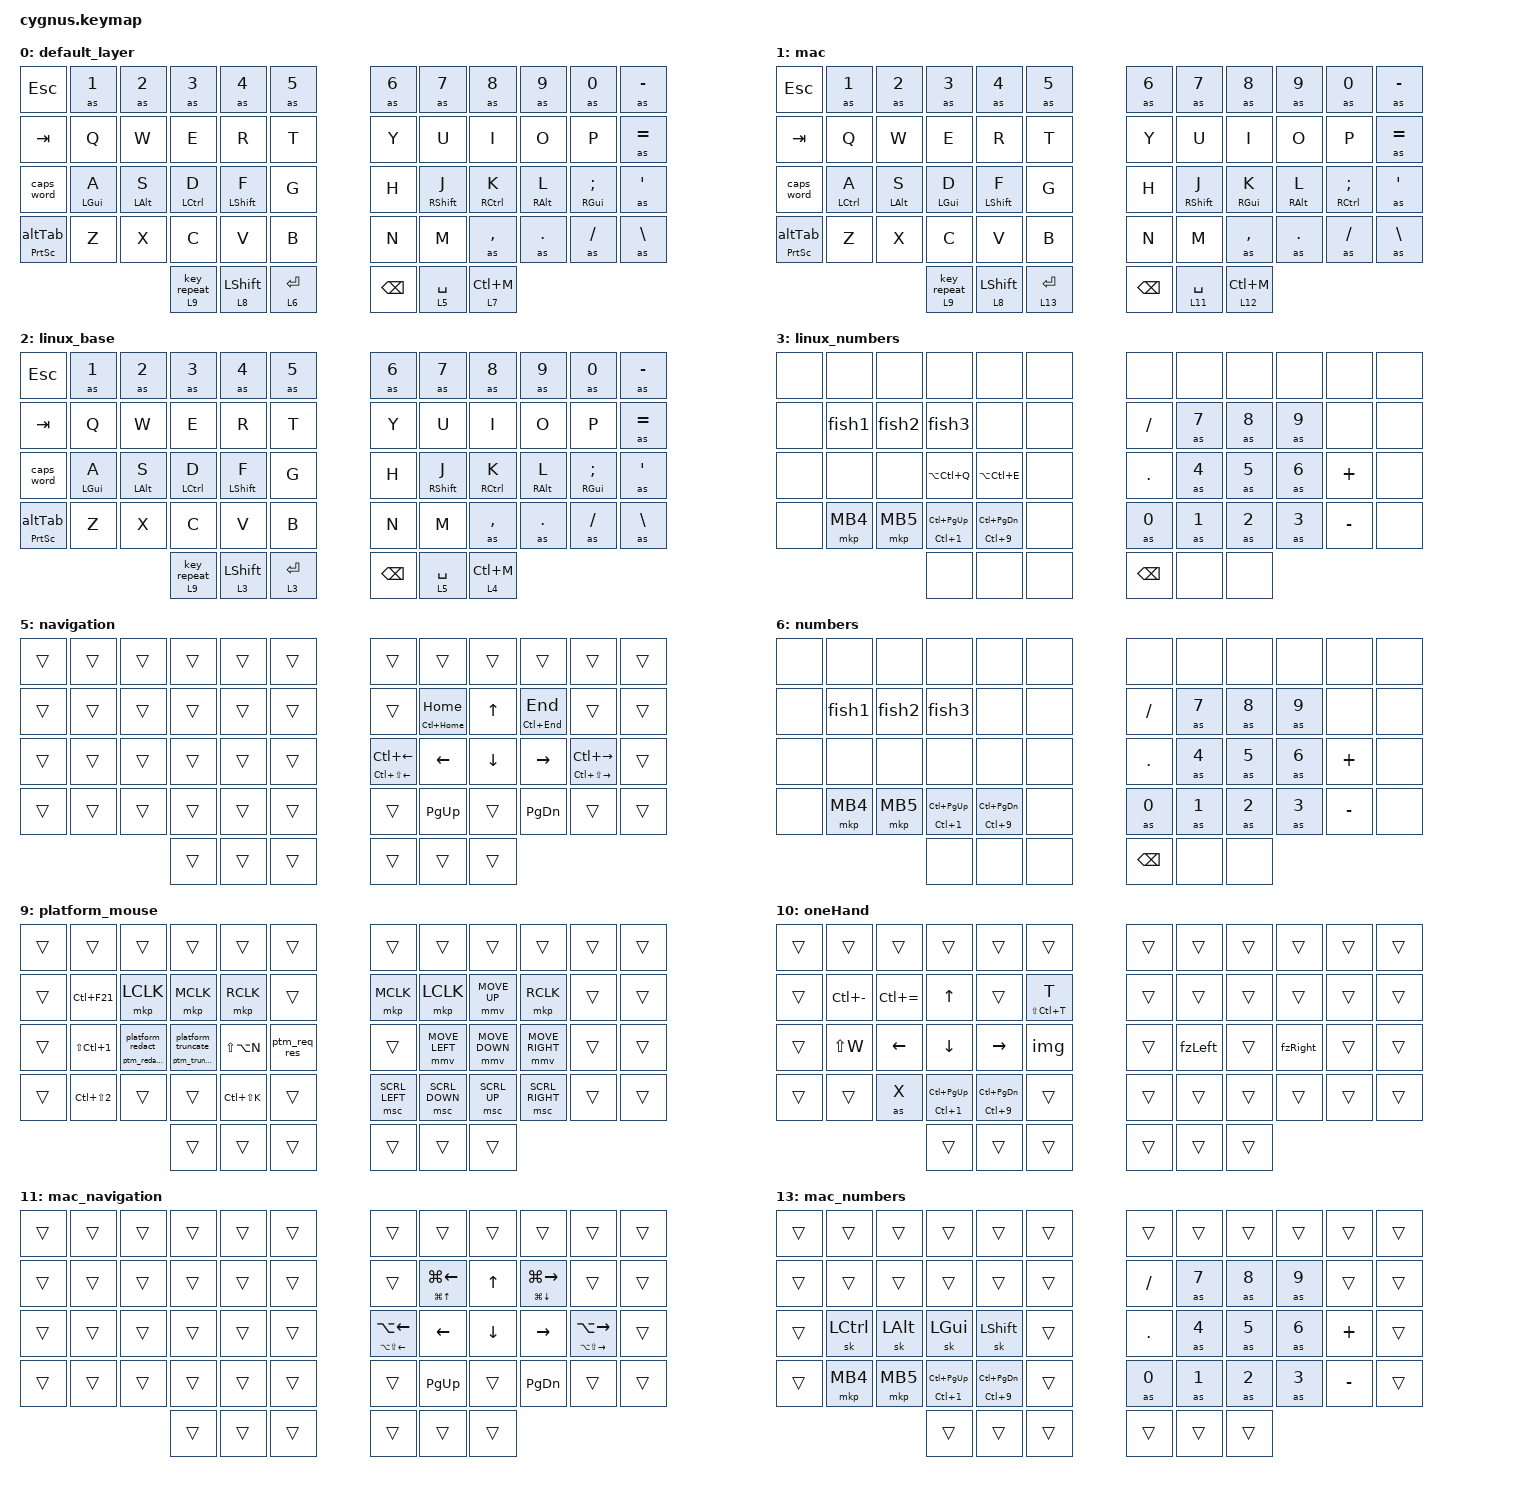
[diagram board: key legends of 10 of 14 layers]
#include <behaviors.dtsi>
#include <dt-bindings/zmk/keys.h>
#include <dt-bindings/zmk/pointing.h>

&sk { quick-release; };

/ {
    combos {
        compatible = "zmk,combos";

        copy {
            bindings = <&kp LC(C)>;
            key-positions = <38 39>;
            layers = <0 2>;
            require-prior-idle-ms = <150>;
        };

        paste {
            bindings = <&kp LC(V)>;
            key-positions = <39 40>;
            layers = <0 2>;
            require-prior-idle-ms = <150>;
        };

        del {
            bindings = <&holdTap LC(DELETE) DEL>;
            key-positions = <40 41>;
        };

        backtickTilde {
            bindings = <&as GRAVE>;
            key-positions = <13 14 15>;
        };

        oneHand {
            bindings = <&tog 10>;
            key-positions = <0 1 11 10>;
            layers = <0 10 2>;
        };

        esc {
            bindings = <&kp ESCAPE>;
            key-positions = <13 14>;
        };

        caps_word {
            bindings = <&caps_word>;
            key-positions = <31 28>;
        };

        ps_at {
            bindings = <&print_alt_tab PRINTSCREEN 0>;
            key-positions = <37 38>;
            layers = <0 2>;
            require-prior-idle-ms = <150>;
        };

        v_desktop_left {
            bindings = <&kp LG(LC(LEFT))>;
            key-positions = <42 43 44>;
            layers = <0 10>;
            require-prior-idle-ms = <150>;
        };

        v_desktop_right {
            bindings = <&kp LG(LC(RIGHT))>;
            key-positions = <43 44 45>;
            layers = <0 10>;
            require-prior-idle-ms = <150>;
        };

        tasks {
            bindings = <&holdTap LG(TAB) LC(LA(TAB))>;
            key-positions = <37 39>;
            require-prior-idle-ms = <200>;
            layers = <0>;
        };

        lbracket {
            bindings = <&as LEFT_BRACKET>;
            key-positions = <17 16>;
            require-prior-idle-ms = <200>;
        };

        rbracket {
            bindings = <&as RIGHT_BRACKET>;
            key-positions = <18 19>;
            require-prior-idle-ms = <200>;
        };

        altf4 {
            bindings = <&kp LA(F4)>;
            key-positions = <14 15 16 19 20 21>;
            require-prior-idle-ms = <200>;
            layers = <0 2>;
        };

        select_line {
            bindings = <&select_line>;
            key-positions = <21 20 19>;
            require-prior-idle-ms = <250>;
            layers = <0 2>;
        };

        mac_cp {
            bindings = <&kp LG(C)>;
            key-positions = <38 39>;
            require-prior-idle-ms = <200>;
            layers = <1>;
        };

        mac_pst {
            bindings = <&kp LG(V)>;
            key-positions = <40 39>;
            require-prior-idle-ms = <200>;
            layers = <1>;
        };

        mission_ctrl {
            bindings = <&hold_tap LC(DOWN) LC(UP_ARROW)>;
            key-positions = <39 37>;
            layers = <1>;
            require-prior-idle-ms = <200>;
        };

        ps_cmd_tab {
            bindings = <&hold_tap LS(LG(LC(NUMBER_4))) LG(TAB)>;
            key-positions = <37 38>;
            layers = <1>;
            require-prior-idle-ms = <200>;
        };

        mac_desktop_left {
            bindings = <&kp LC(LEFT)>;
            key-positions = <42 43 44>;
            layers = <1>;
            require-prior-idle-ms = <200>;
        };

        mac_desktop_right {
            bindings = <&kp LC(RIGHT)>;
            key-positions = <45 44 43>;
            layers = <1>;
            require-prior-idle-ms = <200>;
        };

        mac_sel_line {
            bindings = <&mac_select_line>;
            key-positions = <21 20 19>;
            layers = <1>;
            require-prior-idle-ms = <250>;
        };

        mac_delete_word {
            bindings = <&kp LA(BACKSPACE)>;
            key-positions = <51 32>;
            layers = <1>;
            require-prior-idle-ms = <150>;
        };

        mac_quit {
            bindings = <&hold_tap LG(Q) LG(W)>;
            key-positions = <20 21 19 15 14 16>;
            require-prior-idle-ms = <200>;
            layers = <1>;
        };

        mac_cycle {
            bindings = <&kp LG(GRAVE)>;
            key-positions = <37 38 39>;
            layers = <1>;
            require-prior-idle-ms = <200>;
        };

        mac_show_dock {
            bindings = <&kp LA(LG(D))>;
            key-positions = <39 40 41>;
            layers = <0>;
            require-prior-idle-ms = <150>;
        };

        dash {
            bindings = <&as MINUS>;
            key-positions = <21 20>;
            timeout-ms = <30>;
        };

        as_apos {
            bindings = <&as APOS>;
            key-positions = <32 33>;
        };

        ldr {
            bindings = <&leader1>;
            key-positions = <16 15>;
            layers = <0 1 2>;
            timeout-ms = <30>;
            require-prior-idle-ms = <250>;
        };

        tab {
            bindings = <&kp TAB>;
            key-positions = <26 27>;
            require-prior-idle-ms = <150>;
            timeout-ms = <30>;
        };

        linux_desktop_left {
            bindings = <&kp LC(LA(LEFT))>;
            key-positions = <42 43 44>;
            layers = <2>;
            require-prior-idle-ms = <150>;
        };

        linux_desktop_right {
            bindings = <&kp LC(LA(RIGHT))>;
            key-positions = <43 44 45>;
            layers = <2>;
            require-prior-idle-ms = <150>;
        };

        linux_gui {
            bindings = <&kp LC(LA(DOWN))>;
            key-positions = <37 39>;
            require-prior-idle-ms = <150>;
            layers = <2>;
        };
    };

    behaviors {
        hml: hml {
            compatible = "zmk,behavior-hold-tap";
            label = "HOME_ROW_LEFT";
            bindings = <&kp>, <&kp>;

            #binding-cells = <2>;
            hold-trigger-key-positions = <6 7 8 9 10 11 18 19 20 21 22 23 30 31 32 33 34 35 42 43 44 45 46 47>;
            tapping-term-ms = <180>;
            quick-tap-ms = <175>;
            require-prior-idle-ms = <150>;
            flavor = "balanced";
            hold-trigger-on-release;
        };

        hmr: hmr {
            compatible = "zmk,behavior-hold-tap";
            label = "HOME_ROW_RIGHT";
            bindings = <&kp>, <&kp>;

            #binding-cells = <2>;
            tapping-term-ms = <180>;
            quick-tap-ms = <175>;
            require-prior-idle-ms = <150>;
            flavor = "balanced";
            hold-trigger-key-positions = <0 1 2 3 4 5 12 13 14 15 16 17 24 25 26 27 28 29 36 37 38 39 40 41>;
            hold-trigger-on-release;
        };

        layer_sticky: layer_sticky {
            compatible = "zmk,behavior-hold-tap";
            label = "LAYER_STICKY";
            bindings = <&mo>, <&sk>;

            #binding-cells = <2>;
            tapping-term-ms = <150>;
            flavor = "balanced";
        };

        holdTap: holdTap {
            compatible = "zmk,behavior-hold-tap";
            label = "HOLDTAP";
            bindings = <&kp>, <&kp>;

            #binding-cells = <2>;
            tapping-term-ms = <200>;
        };

        hold_AT: hold_AT {
            compatible = "zmk,behavior-hold-tap";
            label = "HOLD_AT";
            bindings = <&kp>, <&altTab>;

            #binding-cells = <2>;
            tapping-term-ms = <200>;
        };

        as_ht: auto_shift_hold_tap {
            compatible = "zmk,behavior-hold-tap";
            label = "AUTO_SHIFT_HOLD_TAP";
            bindings = <&shift>, <&kp>;

            #binding-cells = <2>;
            tapping-term-ms = <200>;
            flavor = "balanced";
        };

        fz_left: fz_left {
            compatible = "zmk,behavior-hold-tap";
            label = "FZ_LEFT";
            bindings = <&kp>, <&fzLeft>;

            #binding-cells = <2>;
            tapping-term-ms = <200>;
        };

        fz_right: fz_right {
            compatible = "zmk,behavior-hold-tap";
            label = "FZ_RIGHT";
            bindings = <&kp>, <&fzRight>;

            #binding-cells = <2>;
            tapping-term-ms = <200>;
        };

        ac_browser: ac_browser {
            compatible = "zmk,behavior-tap-dance";
            label = "AC_BROWSER";
            #binding-cells = <0>;
            bindings =
                <&holdTap LA(LS(LC(V))) LS(LA(LC(Q)))>,
                <&kp LS(LA(LC(X)))>;
        };

        ac_VMs: ac_VMs {
            compatible = "zmk,behavior-tap-dance";
            label = "AC_VMS";
            #binding-cells = <0>;
            bindings = <&kp LS(LA(LC(W)))>, <&kp LS(LA(LC(I)))>;
        };

        burp_rep: burp_rep {
            compatible = "zmk,behavior-tap-dance";
            label = "BURP_REP";
            #binding-cells = <0>;
            bindings = <&kp LS(LC(R))>, <&kp LC(R)>;
        };

        burp_proxy: burp_proxy {
            compatible = "zmk,behavior-tap-dance";
            label = "BURP_PROXY";
            #binding-cells = <0>;
            bindings = <&kp LS(LC(P))>, <&kp LC(T)>;
        };

        burp_intruder: burp_intruder {
            compatible = "zmk,behavior-tap-dance";
            label = "BURP_INTRUDER";
            #binding-cells = <0>;
            bindings = <&holdTap LC(P) LS(LC(I))>, <&kp LC(I)>;
        };

        burp_org: burp_org {
            compatible = "zmk,behavior-tap-dance";
            label = "BURP_ORG";
            #binding-cells = <0>;
            bindings = <&kp LS(LC(O))>, <&kp LC(O)>;
        };

        burp_send: burp_send {
            compatible = "zmk,behavior-tap-dance";
            label = "BURP_SEND";
            #binding-cells = <0>;
            bindings = <&kp LC(SPACE)>, <&kp LS(LC(SPACE))>;
        };

        burp_dash: burp_dash {
            compatible = "zmk,behavior-tap-dance";
            label = "BURP_DASH";
            #binding-cells = <0>;
            bindings = <&holdTap LS(LC(NUMBER_9)) LC(LS(D))>, <&kp LS(LC(T))>;
        };

        burp_fwd: burp_fwd {
            compatible = "zmk,behavior-tap-dance";
            label = "BURP_FWD";
            #binding-cells = <0>;
            bindings = <&kp LC(F)>, <&kp LS(LC(F))>;
        };

        burp_notes_htmlE: burp_notes_htmlE {
            compatible = "zmk,behavior-tap-dance";
            label = "BURP_NOTES_HTMLE";
            #binding-cells = <0>;
            bindings = <&kp LC(LA(N))>, <&kp LC(LA(H))>;
        };

        mouse_layer_toggle: mouse_layer_toggle {
            compatible = "zmk,behavior-tap-dance";
            label = "MOUSE_LAYER_TOGGLE";
            #binding-cells = <0>;
            bindings = <&lt 9 LG(LS(D))>, <&tog 9>;
        };

        ptm_req_res: ptm_req_res {
            compatible = "zmk,behavior-tap-dance";
            label = "PTM_REQ_RES";
            #binding-cells = <0>;
            bindings = <&ptm_req>, <&ptm_res>;
        };

        truncate: truncate {
            compatible = "zmk,behavior-hold-tap";
            label = "TRUNCATE";
            bindings = <&ptm_truncated>, <&platform_truncate>;

            #binding-cells = <2>;
            tapping-term-ms = <200>;
            flavor = "balanced";
        };

        redact: redact {
            compatible = "zmk,behavior-hold-tap";
            label = "REDACT";
            bindings = <&ptm_redacted>, <&platform_redact>;

            #binding-cells = <2>;
            flavor = "balanced";
            tapping-term-ms = <200>;
        };

        print_alt_tab: print_alt_tab {
            compatible = "zmk,behavior-hold-tap";
            label = "PRINT_ALT_TAB";
            bindings = <&kp>, <&altTab>;

            #binding-cells = <2>;
            flavor = "balanced";
            tapping-term-ms = <150>;
        };

        hrm: hrm {
            compatible = "zmk,behavior-hold-tap";
            label = "HRM";
            bindings = <&kp>, <&kp>;

            #binding-cells = <2>;
            tapping-term-ms = <280>;
            quick-tap-ms = <175>;
            require-prior-idle-ms = <150>;
            flavor = "balanced";
            hold-trigger-on-release;
        };

        ht_layer: ht_layer {
            compatible = "zmk,behavior-hold-tap";
            label = "HT_LAYER";
            bindings = <&mo>, <&kp>;

            #binding-cells = <2>;
            tapping-term-ms = <200>;
            quick-tap-ms = <175>;
            flavor = "tap-preferred";
        };

        hold_tap: hold_tap {
            compatible = "zmk,behavior-hold-tap";
            label = "HOLD_TAP";
            bindings = <&kp>, <&kp>;

            #binding-cells = <2>;
            tapping-term-ms = <180>;
            flavor = "balanced";
        };

        burp_int: burp_int {
            compatible = "zmk,behavior-tap-dance";
            label = "BURP_INT";
            #binding-cells = <0>;
            bindings = <&hold_tap LC(P) LC(LS(I))>, <&kp LC(I)>;

            tapping-term-ms = <300>;
        };

        burp_notes_highlight: burp_notes_highlight {
            compatible = "zmk,behavior-tap-dance";
            label = "BURP_NOTES_HIGHLIGHT";
            #binding-cells = <0>;
            bindings = <&kp LC(LA(N))>, <&kp LC(LA(H))>;

            tapping-term-ms = <300>;
        };

        ac_vm: ac_vm {
            compatible = "zmk,behavior-tap-dance";
            label = "AC_VM";
            #binding-cells = <0>;
            bindings = <&kp LA(LS(LC(W)))>, <&kp LS(LC(LA(I)))>;
        };

        ptm_code_block: ptm_code_block {
            compatible = "zmk,behavior-tap-dance";
            label = "PTM_CODE_BLOCK";
            #binding-cells = <0>;
            bindings = <&ptm_request>, <&ptm_response>;
        };

        caps: caps {
            compatible = "zmk,behavior-hold-tap";
            label = "CAPS";
            bindings = <&caps_word>, <&sk>;

            #binding-cells = <2>;
            tapping-term-ms = <200>;
            flavor = "balanced";
        };

        ps_at: ps_at {
            compatible = "zmk,behavior-hold-tap";
            label = "PS_AT";
            bindings = <&kp>, <&alt_tab>;

            #binding-cells = <2>;
            tapping-term-ms = <200>;
        };

        burp_rep_with_shift: burp_rep_with_shift {
            compatible = "zmk,behavior-hold-tap";
            label = "BURP_REP_WITH_SHIFT";
            bindings = <&kp>, <&burp_rep>;

            #binding-cells = <2>;
            tapping-term-ms = <200>;
            flavor = "balanced";
        };

        fz_left_both: fz_left_both {
            compatible = "zmk,behavior-hold-tap";
            label = "FZ_LEFT_BOTH";
            bindings = <&kp>, <&fz_left>;

            #binding-cells = <2>;
            tapping-term-ms = <200>;
            flavor = "balanced";
        };

        os_shift_layer_change: os_shift_layer_change {
            compatible = "zmk,behavior-hold-tap";
            label = "OS_SHIFT_LAYER_CHANGE";
            bindings = <&mo>, <&sticky_shift>;

            #binding-cells = <2>;
            tapping-term-ms = <200>;
            flavor = "balanced";
        };

        fz_left_macro: fz_left_macro {
            compatible = "zmk,behavior-hold-tap";
            label = "FZ_LEFT_MACRO";
            bindings = <&fz_expand_left>, <&fz_left>;

            #binding-cells = <2>;
            tapping-term-ms = <200>;
            flavor = "balanced";
        };

        fz_right_macro: fz_right_macro {
            compatible = "zmk,behavior-hold-tap";
            label = "FZ_RIGHT_MACRO";
            bindings = <&fz_expand_right>, <&fz_right>;

            #binding-cells = <2>;
            tapping-term-ms = <200>;
            flavor = "balanced";
        };

        repeat_layer: repeat_layer {
            compatible = "zmk,behavior-hold-tap";
            label = "REPEAT_LAYER";
            bindings = <&mo>, <&key_repeat>;

            #binding-cells = <2>;
            tapping-term-ms = <200>;
        };

        leader1: leader1 {
            compatible = "zmk,behavior-leader-key";
            #binding-cells = <0>;

            os_mac {
                sequence = <O M>;
                bindings = <&to 1>;
            };

            os_win {
                sequence = <O W>;
                bindings = <&to 0>;
            };

            os_linux {
                sequence = <O L>;
                bindings = <&to 2>;
            };

            p_netspi {
                sequence = <P N>;
                bindings = <&fish1>;
            };

            p_aws {
                sequence = <P A>;
                bindings = <&fish2>;
            };

            p_mac {
                sequence = <P M>;
                bindings = <&fish3>;
            };

            w_netspi {
                sequence = <W N>;
                bindings = <&word_netspi>;
            };

            w_signoff {
                sequence = <W S>;
                bindings = <&word_signoff_cmd>;
            };

            w_code_block {
                sequence = <W C>;
                bindings = <&ptm_codeBlock>;
            };

            l_check_mem {
                sequence = <L M>;
                bindings = <&linux_check_mem>;
            };

            l_ssh {
                sequence = <L S>;
                bindings = <&linux_ssh>;
            };

            l_check_drives {
                sequence = <L D>;
                bindings = <&linux_check_mounted_drives>;
            };
        };
    };

    macros {
        altTab: altTab {
            compatible = "zmk,behavior-macro";
            #binding-cells = <0>;
            bindings = <&kt LEFT_ALT &kp TAB &kt LEFT_ALT>;
            label = "ALTTAB";
            wait-ms = <200>;
        };

        alt_tab: alt_tab {
            compatible = "zmk,behavior-macro";
            #binding-cells = <0>;
            bindings = <&kt LEFT_ALT &kp TAB &kt LEFT_ALT>;
            label = "ALT_TAB";
            tap-ms = <150>;
        };

        fish1: pw {
            compatible = "zmk,behavior-macro";
            #binding-cells = <0>;
            bindings = <&kp N0 &kp N0 &kp PERIOD &kp N0 &kp N0 &kp N3 &kp A &kp Q &kp H &kp Q &kp C &kp Y &kp B &kp N0 &kp N0 &kp DOT &kp N0 &kp N0>;
            label = "PW";
        };

        shift: new_macro {
            compatible = "zmk,behavior-macro-one-param";
            #binding-cells = <1>;
            bindings =
                <&macro_press>,
                <&kp LEFT_SHIFT>,
                <&macro_tap>,
                <&macro_param_1to1 &kp MACRO_PLACEHOLDER>,
                <&macro_release>,
                <&kp LEFT_SHIFT>;

            label = "NEW_MACRO";
        };

        as: as {
            compatible = "zmk,behavior-macro-one-param";
            #binding-cells = <1>;
            bindings =
                <&macro_press>,
                <&macro_param_1to1 &macro_param_1to2 &as_ht MACRO_PLACEHOLDER MACRO_PLACEHOLDER>,
                <&macro_pause_for_release>,
                <&macro_release>,
                <&macro_param_1to1 &macro_param_1to2 &as_ht MACRO_PLACEHOLDER MACRO_PLACEHOLDER>;

            label = "AS";
        };

        fzLeft: fzLeft {
            compatible = "zmk,behavior-macro";
            #binding-cells = <0>;
            bindings = <&kt LEFT_GUI &kp LEFT &kt LEFT_GUI>;
            label = "FZLEFT";
            tap-ms = <100>;
        };

        fzRight: fzRight {
            compatible = "zmk,behavior-macro";
            #binding-cells = <0>;
            bindings = <&kt LEFT_GUI &kp RIGHT &kt LEFT_GUI>;
            label = "FZRIGHT";
            tap-ms = <100>;
        };

        sticky_shift: sticky_shift {
            compatible = "zmk,behavior-macro";
            #binding-cells = <0>;
            bindings = <&sk LEFT_SHIFT>;
            label = "STICKY_SHIFT";
        };

        fzUp: fzUp {
            compatible = "zmk,behavior-macro";
            #binding-cells = <0>;
            bindings = <&kt LEFT_GUI &kp UP_ARROW &kt LEFT_GUI>;
            label = "FZUP";
            tap-ms = <100>;
        };

        fzDown: fzDown {
            compatible = "zmk,behavior-macro";
            #binding-cells = <0>;
            bindings = <&kt LEFT_GUI &kp DOWN &kt LEFT_GUI>;
            label = "FZDOWN";
            tap-ms = <100>;
        };

        fz_expand_left: fz_expand_left {
            compatible = "zmk,behavior-macro";
            #binding-cells = <0>;
            bindings = <&kt LEFT_GUI &kt LEFT_ALT &kt LCTRL &kt LEFT &kt LEFT_GUI &kt LALT &kt LCTRL>;
            label = "FZ_EXPAND_LEFT";
            tap-ms = <50>;
        };

        fz_expand_right: fz_expand_right {
            compatible = "zmk,behavior-macro";
            #binding-cells = <0>;
            bindings = <&kt LEFT_GUI &kt LEFT_ALT &kt LCTRL &kt RIGHT &kt LEFT_GUI &kt LALT &kt LCTRL>;
            label = "FZ_EXPAND_RIGHT";
            tap-ms = <50>;
        };

        img: img {
            compatible = "zmk,behavior-macro";
            #binding-cells = <0>;
            bindings = <&mkp RCLK &kp I>;
            label = "IMG";
            tap-ms = <300>;
        };

        close: close {
            compatible = "zmk,behavior-macro";
            #binding-cells = <0>;
            bindings = <&kt LEFT_ALT &kp F4 &kt LEFT_ALT>;
            label = "CLOSE";
            tap-ms = <200>;
        };

        select_line: select_line {
            compatible = "zmk,behavior-macro";
            #binding-cells = <0>;
            bindings = <&kp HOME &kp LS(END)>;
            label = "SELECT_LINE";
            tap-ms = <100>;
        };

        double_click: double_click {
            compatible = "zmk,behavior-macro";
            #binding-cells = <0>;
            bindings = <&mkp MB1 &mkp MB1>;
            label = "DOUBLE_CLICK";
            tap-ms = <50>;
        };

        shift_click: shift_click {
            compatible = "zmk,behavior-macro";
            #binding-cells = <0>;
            bindings = <&kt LC(LEFT_SHIFT) &mkp MB1 &kt LC(LEFT_SHIFT)>;
            label = "SHIFT_CLICK";
        };

        mac_select_line: mac_select_line {
            compatible = "zmk,behavior-macro";
            #binding-cells = <0>;
            bindings = <&kp LG(LEFT) &kp LS(LG(RIGHT))>;
            label = "MAC_SELECT_LINE";
        };

        ptm_codeBlock: ptm_codeBlock {
            compatible = "zmk,behavior-macro";
            #binding-cells = <0>;
            bindings = <&kp GRAVE &kp GRAVE &kp GRAVE &kp ENTER &kp ENTER &kp GRAVE &kp GRAVE &kp GRAVE &kp UP_ARROW>;
            label = "PTM_CODEBLOCK";
        };

        fish2: pw2 {
            compatible = "zmk,behavior-macro";
            #binding-cells = <0>;
            bindings = <&kp N3 &kp A &kp Q &kp H &kp Q &kp C &kp Y &kp B &kp N0 &kp DOT &kp N0>;
            label = "PW2";
        };

        ptm_req: ptm_req {
            compatible = "zmk,behavior-macro";
            #binding-cells = <0>;
            bindings = <&kp STAR &kp STAR &kp LS(R) &kp E &kp Q &kp U &kp E &kp S &kp T &kp COLON &kp STAR &kp STAR &kp RET &kp GRAVE &kp GRAVE &kp GRAVE &kp RET &kp RET &kp GRAVE &kp GRAVE &kp GRAVE &kp UP_ARROW>;
            label = "PTM_REQ";
        };

        ptm_request: ptm_request {
            compatible = "zmk,behavior-macro";
            #binding-cells = <0>;
            bindings = <&kp STAR &kp STAR &kp LS(R) &kp E &kp Q &kp U &kp E &kp S &kp T &kp COLON &kp STAR &kp STAR &kp RET &kp GRAVE &kp GRAVE &kp GRAVE &kp RET &kp RET &kp GRAVE &kp GRAVE &kp GRAVE &kp UP_ARROW>;
            label = "PTM_REQUEST";
        };

        ptm_res: ptm_res {
            compatible = "zmk,behavior-macro";
            #binding-cells = <0>;
            bindings = <&kp STAR &kp STAR &kp LS(R) &kp E &kp S &kp P &kp O &kp N &kp S &kp E &kp COLON &kp STAR &kp STAR &kp RET &kp GRAVE &kp GRAVE &kp GRAVE &kp RET &kp RET &kp GRAVE &kp GRAVE &kp GRAVE &kp UP_ARROW>;
            label = "PTM_RES";
        };

        ptm_response: ptm_response {
            compatible = "zmk,behavior-macro";
            #binding-cells = <0>;
            bindings = <&kp STAR &kp STAR &kp LS(R) &kp E &kp S &kp P &kp O &kp N &kp S &kp E &kp COLON &kp STAR &kp STAR &kp RET &kp GRAVE &kp GRAVE &kp GRAVE &kp RET &kp RET &kp GRAVE &kp GRAVE &kp GRAVE &kp UP_ARROW>;
            label = "PTM_RESPONSE";
        };

        ptm_redacted: ptm_redacted {
            compatible = "zmk,behavior-macro";
            #binding-cells = <0>;
            bindings = <&kp LBKT &kp LS(R) &kp LS(E) &kp LS(D) &kp LS(A) &kp LS(C) &kp LS(T) &kp LS(E) &kp LS(D) &kp RBKT>;
            label = "PTM_REDACTED";
        };

        ptm_truncated: ptm_truncated {
            compatible = "zmk,behavior-macro";
            #binding-cells = <0>;
            bindings = <&kp LBKT &kp LS(T) &kp LS(R) &kp LS(U) &kp LS(N) &kp LS(C) &kp LS(A) &kp LS(T) &kp LS(E) &kp LS(D) &kp RBKT>;
            label = "PTM_TRUNCATED";
        };

        platform_truncate: platform_truncate {
            compatible = "zmk,behavior-macro";
            #binding-cells = <0>;
            bindings = <&kp LS(LA(T))>;
            label = "PLATFORM_TRUNCATE";
        };

        platform_redact: platform_redact {
            compatible = "zmk,behavior-macro";
            #binding-cells = <0>;
            bindings = <&kp LS(LA(R))>;
            label = "PLATFORM_REDACT";
        };

        fish3: fish3 {
            compatible = "zmk,behavior-macro";
            #binding-cells = <0>;
            bindings = <&kp N0 &kp N0 &kp DOT &kp N0 &kp N0 &kp N3 &kp A &kp Q &kp H &kp Q &kp C &kp Y &kp LS(B) &kp N0 &kp N0 &kp DOT &kp N0 &kp N0>;
            label = "FISH3";
        };

        word_netspi: word_netspi {
            compatible = "zmk,behavior-macro";
            #binding-cells = <0>;
            bindings = <&kp LS(N) &kp E &kp T &kp LS(S) &kp LS(P) &kp LS(I)>;
            label = "WORD_NETSPI";
        };

        word_signoff_cmd: word_signoff_cmd {
            compatible = "zmk,behavior-macro";
            #binding-cells = <0>;
            bindings = <&kp GRAVE &kp FSLH &kp S &kp D &kp L &kp MINUS &kp M &kp E &kp D &kp I &kp U &kp M &kp MINUS &kp S &kp I &kp G &kp N &kp O &kp F &kp F &kp GRAVE>;
            label = "WORD_SIGNOFF_CMD";
        };

        linux_check_mem: linux_check_mem {
            compatible = "zmk,behavior-macro";
            #binding-cells = <0>;
            bindings = <&kp F &kp R &kp E &kp E &kp SPACE &kp MINUS &kp H>;
            label = "LINUX_CHECK_MEM";
        };

        linux_ssh: linux_ssh {
            compatible = "zmk,behavior-macro";
            #binding-cells = <0>;
            bindings = <&kp S &kp S &kp H &kp SPACE &kp S &kp U &kp N &kp G &kp AT &kp S &kp U &kp N &kp G &kp MINUS &kp S &kp E &kp R &kp V &kp E &kp R>;
            label = "LINUX_SSH";
        };

        linux_check_mounted_drives: linux_check_mounted_drives {
            compatible = "zmk,behavior-macro";
            #binding-cells = <0>;
            bindings = <&kp L &kp S &kp B &kp L &kp K &kp SPACE &kp MINUS &kp F>;
            label = "LINUX_CHECK_MOUNTED_DRIVES";
        };
    };

    keymap {
        compatible = "zmk,keymap";

        default_layer {
            // -----------------------------------------------------------------------------------------
            // |  ESC |  1  |  2  |  3  |  4  |  5  |   |  6  |  7   |  8  |  9  |  0  |  ?   |
            // |  TAB |  Q  |  W  |  E  |  R  |  T  |   |  Y  |  U   |  I  |  O  |  P  | BKSP |
            // | CTRL |  A  |  S  |  D  |  F  |  G  |   |  H  |  J   |  K  |  L  |  ;  |  '   |
            // | SHFT |  Z  |  X  |  C  |  V  |  B  |   |  N  |  M   |  ,  |  .  |  /  | ESC  |
            //                    | GUI | LWR | SPC |   | ENT | RSE  | ALT |

            bindings = <
&kp ESCAPE              &as N1           &as N2           &as N3               &as N4                      &as N5         &as N6         &as N7              &as N8        &as N9            &as N0               &as MINUS
&kp TAB                 &kp Q            &kp W            &kp E                &kp R                       &kp T          &kp Y          &kp U               &kp I         &kp O             &kp P                &as EQUAL
&caps_word              &hml LEFT_GUI A  &hml LEFT_ALT S  &hml LEFT_CONTROL D  &hml LEFT_SHIFT F           &kp G          &kp H          &hmr RIGHT_SHIFT J  &hmr RCTRL K  &hmr RIGHT_ALT L  &hmr RIGHT_GUI SEMI  &as SQT
&hold_AT PRINTSCREEN 0  &kp Z            &kp X            &kp C                &kp V                       &kp B          &kp N          &kp M               &as COMMA     &as DOT           &as SLASH            &as BSLH
                                                          &repeat_layer 9 0    &layer_sticky 8 LEFT_SHIFT  &lt 6 ENTER    &kp BACKSPACE  &lt 5 SPACE         &lt 7 LC(M)
            >;
        };

        mac {
            bindings = <
&kp ESCAPE              &as N1        &as N2           &as N3             &as N4                      &as N5          &as N6         &as N7              &as N8            &as N9            &as N0           &as MINUS
&kp TAB                 &kp Q         &kp W            &kp E              &kp R                       &kp T           &kp Y          &kp U               &kp I             &kp O             &kp P            &as EQUAL
&caps_word              &hml LCTRL A  &hml LEFT_ALT S  &hml LEFT_GUI D    &hml LEFT_SHIFT F           &kp G           &kp H          &hmr RIGHT_SHIFT J  &hmr RIGHT_GUI K  &hmr RIGHT_ALT L  &hmr RCTRL SEMI  &as SQT
&hold_AT PRINTSCREEN 0  &kp Z         &kp X            &kp C              &kp V                       &kp B           &kp N          &kp M               &as COMMA         &as DOT           &as SLASH        &as BSLH
                                                       &repeat_layer 9 0  &layer_sticky 8 LEFT_SHIFT  &lt 13 ENTER    &kp BACKSPACE  &lt 11 SPACE        &lt 12 LC(M)
            >;
        };

        linux_base {
            bindings = <
&kp ESCAPE              &as N1           &as N2           &as N3               &as N4                      &as N5         &as N6         &as N7              &as N8        &as N9            &as N0               &as MINUS
&kp TAB                 &kp Q            &kp W            &kp E                &kp R                       &kp T          &kp Y          &kp U               &kp I         &kp O             &kp P                &as EQUAL
&caps_word              &hml LEFT_GUI A  &hml LEFT_ALT S  &hml LEFT_CONTROL D  &hml LEFT_SHIFT F           &kp G          &kp H          &hmr RIGHT_SHIFT J  &hmr RCTRL K  &hmr RIGHT_ALT L  &hmr RIGHT_GUI SEMI  &as SQT
&hold_AT PRINTSCREEN 0  &kp Z            &kp X            &kp C                &kp V                       &kp B          &kp N          &kp M               &as COMMA     &as DOT           &as SLASH            &as BSLH
                                                          &repeat_layer 9 0    &layer_sticky 3 LEFT_SHIFT  &lt 3 ENTER    &kp BACKSPACE  &lt 5 SPACE         &lt 4 LC(M)
            >;
        };

        linux_numbers {
            bindings = <
&none  &none     &none     &none                            &none                          &none    &none          &none         &none         &none         &none      &none
&none  &fish1    &fish2    &fish3                           &none                          &none    &kp SLASH      &as N7        &as N8        &as N9        &none      &none
&none  &none     &none     &kp LA(LC(Q))                    &kp LA(LC(E))                  &none    &kp PERIOD     &as NUMBER_4  &as N5        &as NUMBER_6  &kp PLUS   &none
&none  &mkp MB4  &mkp MB5  &holdTap LC(NUMBER_1) LC(PG_UP)  &holdTap LC(N9) LC(PAGE_DOWN)  &none    &as N0         &as NUMBER_1  &as NUMBER_2  &as NUMBER_3  &kp MINUS  &none
                           &none                            &none                          &none    &kp BACKSPACE  &none         &none
            >;
        };

        linux_media {
            bindings = <
&trans  &trans                    &trans                       &trans                    &trans                         &trans    &trans  &trans             &trans            &trans           &trans  &trans
&trans  &kp LC(LG(LA(NUMBER_1)))  &kp LC(LG(LA(NUMBER_2)))     &kp LC(LG(LA(NUMBER_3)))  &kp LC(LA(LG(NUMBER_4)))       &trans    &trans  &kp C_VOLUME_DOWN  &kp C_MUTE        &kp C_VOLUME_UP  &trans  &trans
&trans  &trans                    &fz_left LA(LC(LG(LEFT))) 0  &trans                    &fz_right LA(LC(LG(RIGHT))) 0  &trans    &trans  &kp C_PREV         &kp C_PLAY_PAUSE  &kp C_NEXT       &trans  &trans
&trans  &trans                    &trans                       &trans                    &trans                         &trans    &trans  &trans             &trans            &trans           &trans  &trans
                                                               &trans                    &trans                         &trans    &trans  &trans             &trans
            >;
        };

        navigation {
            // -----------------------------------------------------------------------------------------
            // |  TAB |  F1 |  F2 |  F3 |  F4 |  F5 |   |  F6 |  F7 |  F8 |  F9 | F10 | BKSP |
            // |  TAB |  1  |  2  |  3  |  4  |  5  |   |  6  |  7  |  8  |  9  |  0  | BKSP |
            // | BTCLR| BT1 | BT2 | BT3 | BT4 | BT5 |   | LFT | DWN |  UP | RGT |     |      |
            // | SHFT |     |     |     |     |     |   |     |     |     |     |     |      |
            //                    | GUI |     | SPC |   | ENT |     | ALT |

            bindings = <
&trans  &trans  &trans  &trans  &trans  &trans    &trans                          &trans                  &trans        &trans                &trans                            &trans
&trans  &trans  &trans  &trans  &trans  &trans    &trans                          &holdTap LC(HOME) HOME  &kp UP_ARROW  &holdTap LC(END) END  &trans                            &trans
&trans  &trans  &trans  &trans  &trans  &trans    &holdTap LC(LS(LEFT)) LC(LEFT)  &kp LEFT                &kp DOWN      &kp RIGHT             &holdTap LC(LS(RIGHT)) LC(RIGHT)  &trans
&trans  &trans  &trans  &trans  &trans  &trans    &trans                          &kp PAGE_UP             &trans        &kp PAGE_DOWN         &trans                            &trans
                        &trans  &trans  &trans    &trans                          &trans                  &trans
            >;
        };

        numbers {
            bindings = <
&none  &none     &none     &none                            &none                          &none    &none          &none         &none         &none         &none      &none
&none  &fish1    &fish2    &fish3                           &none                          &none    &kp SLASH      &as N7        &as N8        &as N9        &none      &none
&none  &none     &none     &none                            &none                          &none    &kp PERIOD     &as NUMBER_4  &as N5        &as NUMBER_6  &kp PLUS   &none
&none  &mkp MB4  &mkp MB5  &holdTap LC(NUMBER_1) LC(PG_UP)  &holdTap LC(N9) LC(PAGE_DOWN)  &none    &as N0         &as NUMBER_1  &as NUMBER_2  &as NUMBER_3  &kp MINUS  &none
                           &none                            &none                          &none    &kp BACKSPACE  &none         &none
            >;
        };

        fz_media_browser {
            // -----------------------------------------------------------------------------------------
            // |  TAB |  !  |  @  |  #  |  $  |  %  |   |  ^  |  &  |  *  |  (  |  )  | BKSP |
            // | CTRL |     |     |     |     |     |   |  -  |  =  |  [  |  ]  |  \  |  `   |
            // | SHFT |     |     |     |     |     |   |  _  |  +  |  {  |  }  | "|" |  ~   |
            //                    | GUI |     | SPC |   | ENT |     | ALT |

            bindings = <
&trans  &trans  &trans                       &trans   &trans                         &trans    &trans  &trans             &trans            &trans           &trans  &trans
&trans  &trans  &trans                       &fzUp    &trans                         &trans    &trans  &kp C_VOLUME_DOWN  &kp C_MUTE        &kp C_VOLUME_UP  &trans  &trans
&trans  &trans  &fz_left LA(LC(LG(LEFT))) 0  &fzDown  &fz_right LA(LC(LG(RIGHT))) 0  &trans    &trans  &kp C_PREV         &kp C_PLAY_PAUSE  &kp C_NEXT       &trans  &trans
&trans  &trans  &trans                       &trans   &trans                         &trans    &trans  &trans             &trans            &trans           &trans  &trans
                                             &trans   &trans                         &trans    &trans  &trans             &trans
            >;
        };

        burp_appChange {
            bindings = <
&trans  &trans                 &trans             &trans                        &trans      &trans                                  &trans         &trans             &trans             &trans                                &trans                                &trans
&trans  &kp LC(LA(P))          &kp LC(LS(Y))      &holdTap LC(LS(A)) LC(LS(E))  &burp_dash  &kp LS(LC(NUMBER_9))                    &trans         &trans             &kp LC(LA(LS(G)))  &trans                                &trans                                &trans
&trans  &burp_org              &burp_intruder     &burp_proxy                   &burp_rep   &kp LS(F13)                             &ac_VMs        &kp LA(LS(LC(C)))  &kp LA(LC(LS(B)))  &kp LA(LS(LC(T)))                     &holdTap LA(LS(LC(A))) LC(LA(LS(Z)))  &kp LA(LC(LS(E)))
&trans  &burp_notes_highlight  &kp LC(LS(LA(L)))  &burp_fwd                     &burp_send  &holdTap LC(LA(W)) LC(LS(BACKSLASH))    &kp LS(LC(A))  &ac_browser        &kp LS(LC(LA(S)))  &holdTap LS(LA(LC(O))) LS(LA(LC(P)))  &kp LA(LS(LC(V)))                     &kp LA(LS(LC(F)))
                                                  &trans                        &trans      &trans                                  &trans         &trans             &trans
            >;
        };

        platform_mouse {
            bindings = <
&trans  &trans                &trans       &trans         &trans         &trans          &trans          &trans          &trans          &trans           &trans  &trans
&trans  &kp LC(F21)           &mkp LCLK    &mkp MCLK      &mkp RCLK      &trans          &mkp MCLK       &mkp LCLK       &mmv MOVE_UP    &mkp RCLK        &trans  &trans
&trans  &kp LS(LC(NUMBER_1))  &redact 0 0  &truncate 0 0  &kp LS(LA(N))  &ptm_req_res    &trans          &mmv MOVE_LEFT  &mmv MOVE_DOWN  &mmv MOVE_RIGHT  &trans  &trans
&trans  &kp LC(LS(NUMBER_2))  &trans       &trans         &kp LC(LS(K))  &trans          &msc SCRL_LEFT  &msc SCRL_DOWN  &msc SCRL_UP    &msc SCRL_RIGHT  &trans  &trans
                                           &trans         &trans         &trans          &trans          &trans          &trans
            >;
        };

        oneHand {
            bindings = <
&trans  &trans         &trans         &trans                             &trans                               &trans                  &trans  &trans   &trans  &trans    &trans  &trans
&trans  &kp LC(MINUS)  &kp LC(EQUAL)  &kp UP_ARROW                       &trans                               &holdTap LS(LC(T)) T    &trans  &trans   &trans  &trans    &trans  &trans
&trans  &kp LS(W)      &kp LEFT       &kp DOWN                           &kp RIGHT                            &img                    &trans  &fzLeft  &trans  &fzRight  &trans  &trans
&trans  &trans         &as X          &holdTap LC(NUMBER_1) LC(PAGE_UP)  &holdTap LC(NUMBER_9) LC(PAGE_DOWN)  &trans                  &trans  &trans   &trans  &trans    &trans  &trans
                                      &trans                             &trans                               &trans                  &trans  &trans   &trans
            >;
        };

        mac_navigation {
            bindings = <
&trans  &trans  &trans  &trans  &trans  &trans    &trans                          &trans                          &trans        &trans                       &trans                            &trans
&trans  &trans  &trans  &trans  &trans  &trans    &trans                          &holdTap LG(UP_ARROW) LG(LEFT)  &kp UP_ARROW  &holdTap LG(DOWN) LG(RIGHT)  &trans                            &trans
&trans  &trans  &trans  &trans  &trans  &trans    &holdTap LA(LS(LEFT)) LA(LEFT)  &kp LEFT                        &kp DOWN      &kp RIGHT                    &holdTap LA(LS(RIGHT)) LA(RIGHT)  &trans
&trans  &trans  &trans  &trans  &trans  &trans    &trans                          &kp PAGE_UP                     &trans        &kp PAGE_DOWN                &trans                            &trans
                        &trans  &trans  &trans    &trans                          &trans                          &trans
            >;
        };

        mac_media {
            bindings = <
&trans  &trans  &trans                &trans                    &trans                 &trans    &trans  &trans             &trans            &trans           &trans  &trans
&trans  &trans  &trans                &kp LC(LS(LG(UP_ARROW)))  &trans                 &trans    &trans  &kp C_VOLUME_DOWN  &kp C_MUTE        &kp C_VOLUME_UP  &trans  &trans
&trans  &trans  &kp LG(LC(LS(LEFT)))  &kp LG(LC(LS(DOWN)))      &kp LC(LG(LS(RIGHT)))  &trans    &trans  &kp C_PREV         &kp C_PLAY_PAUSE  &kp C_NEXT       &trans  &trans
&trans  &trans  &kp LC(LG(LS(E)))     &kp LC(LG(LS(M)))         &kp LC(LG(LS(U)))      &trans    &trans  &trans             &trans            &trans           &trans  &trans
                                      &trans                    &trans                 &trans    &trans  &trans             &trans
            >;
        };

        mac_numbers {
            bindings = <
&trans  &trans     &trans        &trans                           &trans                     &trans    &trans    &trans  &trans  &trans  &trans     &trans
&trans  &trans     &trans        &trans                           &trans                     &trans    &kp FSLH  &as N7  &as N8  &as N9  &trans     &trans
&trans  &sk LCTRL  &sk LEFT_ALT  &sk LEFT_GUI                     &sk LEFT_SHIFT             &trans    &kp DOT   &as N4  &as N5  &as N6  &kp PLUS   &trans
&trans  &mkp MB4   &mkp MB5      &holdTap LC(NUMBER_1) LC(PG_UP)  &holdTap LC(N9) LC(PG_DN)  &trans    &as N0    &as N1  &as N2  &as N3  &kp MINUS  &trans
                                 &trans                           &trans                     &trans    &trans    &trans  &trans
            >;
        };
    };
};
